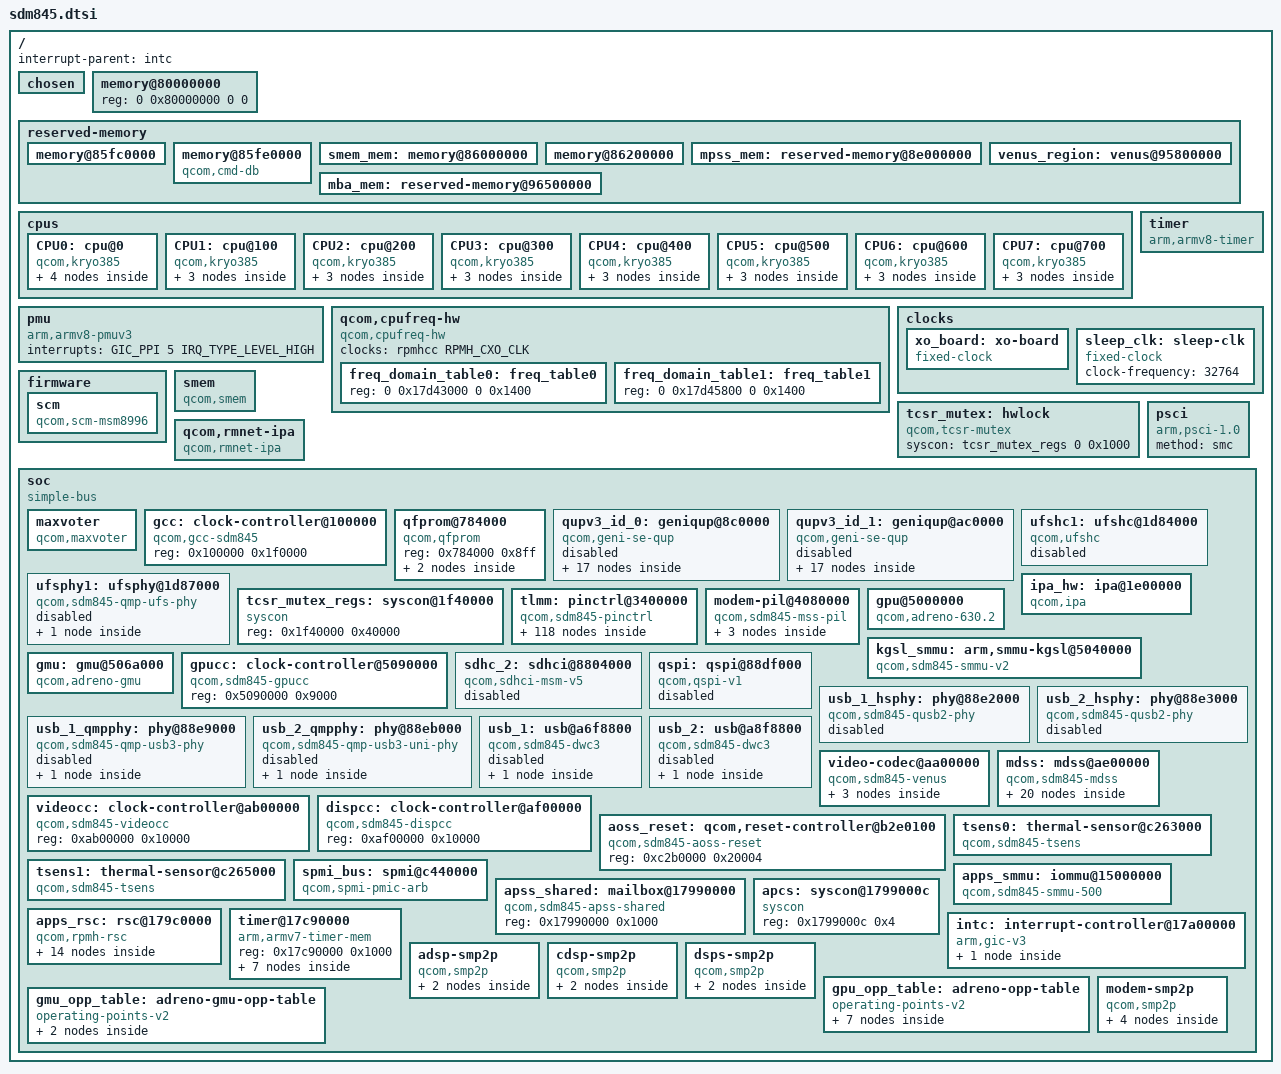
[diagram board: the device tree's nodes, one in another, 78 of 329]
// SPDX-License-Identifier: GPL-2.0
/*
 * SDM845 SoC device tree source
 *
 * Copyright (c) 2018, The Linux Foundation. All rights reserved.
 */

#include <dt-bindings/clock/qcom,dispcc-sdm845.h>
#include <dt-bindings/clock/qcom,gcc-sdm845.h>
#include <dt-bindings/clock/qcom,gpucc-sdm845.h>
#include <dt-bindings/clock/qcom,rpmh.h>
#include <dt-bindings/clock/qcom,videocc-sdm845.h>
#include <dt-bindings/gpio/gpio.h>
#include <dt-bindings/interrupt-controller/arm-gic.h>
#include <dt-bindings/phy/phy-qcom-qusb2.h>
#include <dt-bindings/power/qcom-rpmpd.h>
#include <dt-bindings/reset/qcom,sdm845-aoss.h>
#include <dt-bindings/soc/qcom,rpmh-rsc.h>
#include <dt-bindings/soc/qcom,ipa.h>

/ {
	interrupt-parent = <&intc>;

	#address-cells = <2>;
	#size-cells = <2>;

	chosen { };

	memory@80000000 {
		device_type = "memory";
		/* We expect the bootloader to fill in the size */
		reg = <0 0x80000000 0 0>;
	};

	reserved-memory {
		#address-cells = <2>;
		#size-cells = <2>;
		ranges;

		memory@85fc0000 {
			reg = <0 0x85fc0000 0 0x20000>;
			no-map;
		};

		memory@85fe0000 {
			compatible = "qcom,cmd-db";
			reg = <0x0 0x85fe0000 0x0 0x20000>;
			no-map;
		};

		smem_mem: memory@86000000 {
			reg = <0x0 0x86000000 0x0 0x200000>;
			no-map;
		};

		memory@86200000 {
			reg = <0 0x86200000 0 0x2d00000>;
			no-map;
		};

		mpss_mem: reserved-memory@8e000000 {
			no-map;
			reg = <0 0x8e000000 0 0x7800000>;
		};

		venus_region: venus@95800000 {
			reg = <0x0 0x95800000 0x0 0x500000>;
			no-map;
		};

		mba_mem: reserved-memory@96500000 {
			no-map;
			reg = <0 0x96500000 0 0x200000>;
		};
	};

	cpus {
		#address-cells = <2>;
		#size-cells = <0>;

		CPU0: cpu@0 {
			device_type = "cpu";
			compatible = "qcom,kryo385";
			reg = <0x0 0x0>;
			enable-method = "psci";
			efficiency = <1024>;
			next-level-cache = <&L2_0>;
			qcom,freq-domain = <&freq_domain_table0>;

			L2_0: l2-cache {
				compatible = "cache";
				next-level-cache = <&L3_0>;

				L3_0: l3-cache {
				      compatible = "cache";
				};
			};

			L1_I_0: l1-icache {
				compatible = "cache";
				qcom,dump-size = <0x9000>;
			};

			L1_D_0: l1-dcache {
				compatible = "cache";
				qcom,dump-size = <0x9000>;
			};
		};

		CPU1: cpu@100 {
			device_type = "cpu";
			compatible = "qcom,kryo385";
			reg = <0x0 0x100>;
			enable-method = "psci";
			efficiency = <1024>;
			next-level-cache = <&L2_100>;
			qcom,freq-domain = <&freq_domain_table0>;

			L2_100: l2-cache {
				compatible = "cache";
				next-level-cache = <&L3_0>;
			};

			L1_I_100: l1-icache {
				compatible = "cache";
				qcom,dump-size = <0x9000>;
			};

			L1_D_100: l1-dcache {
				compatible = "cache";
				qcom,dump-size = <0x9000>;
			};
		};

		CPU2: cpu@200 {
			device_type = "cpu";
			compatible = "qcom,kryo385";
			reg = <0x0 0x200>;
			enable-method = "psci";
			efficiency = <1024>;
			next-level-cache = <&L2_200>;
			qcom,freq-domain = <&freq_domain_table0>;

			L2_200: l2-cache {
				compatible = "cache";
				next-level-cache = <&L3_0>;
			};

			L1_I_200: l1-icache {
				compatible = "cache";
				qcom,dump-size = <0x9000>;
			};

			L1_D_200: l1-dcache {
				compatible = "cache";
				qcom,dump-size = <0x9000>;
			};
		};

		CPU3: cpu@300 {
			device_type = "cpu";
			compatible = "qcom,kryo385";
			reg = <0x0 0x300>;
			enable-method = "psci";
			efficiency = <1024>;
			next-level-cache = <&L2_300>;
			qcom,freq-domain = <&freq_domain_table0>;

			L2_300: l2-cache {
				compatible = "cache";
				next-level-cache = <&L3_0>;
			};

			L1_I_300: l1-icache {
				compatible = "cache";
				qcom,dump-size = <0x9000>;
			};
			L1_D_300: l1-dcache {
				compatible = "cache";
				qcom,dump-size = <0x9000>;
			};
		};

		CPU4: cpu@400 {
			device_type = "cpu";
			compatible = "qcom,kryo385";
			reg = <0x0 0x400>;
			enable-method = "psci";
			efficiency = <1740>;
			next-level-cache = <&L2_400>;
			qcom,freq-domain = <&freq_domain_table1>;

			L2_400: l2-cache {
				compatible = "cache";
				next-level-cache = <&L3_0>;
			};

			L1_I_400: l1-icache {
				compatible = "cache";
				qcom,dump-size = <0x12000>;
			};

			L1_D_400: l1-dcache {
				compatible = "cache";
				qcom,dump-size = <0x12000>;
			};
		};

		CPU5: cpu@500 {
			device_type = "cpu";
			compatible = "qcom,kryo385";
			reg = <0x0 0x500>;
			enable-method = "psci";
			efficiency = <1740>;
			next-level-cache = <&L2_500>;
			qcom,freq-domain = <&freq_domain_table1>;

			L2_500: l2-cache {
				compatible = "cache";
				next-level-cache = <&L3_0>;
			};

			L1_I_500: l1-icache {
				compatible = "cache";
				qcom,dump-size = <0x12000>;
			};

			L1_D_500: l1-dcache {
				compatible = "cache";
				qcom,dump-size = <0x12000>;
			};
		};

		CPU6: cpu@600 {
			device_type = "cpu";
			compatible = "qcom,kryo385";
			reg = <0x0 0x600>;
			enable-method = "psci";
			efficiency = <1740>;
			next-level-cache = <&L2_600>;
			qcom,freq-domain = <&freq_domain_table1>;

			L2_600: l2-cache {
				compatible = "cache";
				next-level-cache = <&L3_0>;
			};

			L1_I_600: l1-icache {
				compatible = "cache";
				qcom,dump-size = <0x12000>;
			};

			L1_D_600: l1-dcache {
				compatible = "cache";
				qcom,dump-size = <0x12000>;
			};
		};

		CPU7: cpu@700 {
			device_type = "cpu";
			compatible = "qcom,kryo385";
			reg = <0x0 0x700>;
			enable-method = "psci";
			efficiency = <1740>;
			next-level-cache = <&L2_700>;
			qcom,freq-domain = <&freq_domain_table1>;

			L2_700: l2-cache {
				compatible = "cache";
				next-level-cache = <&L3_0>;
			};

			L1_I_700: l1-icache {
				compatible = "cache";
				qcom,dump-size = <0x12000>;
			};

			L1_D_700: l1-dcache {
				compatible = "cache";
				qcom,dump-size = <0x12000>;
			};
		};
	};

	pmu {
		compatible = "arm,armv8-pmuv3";
		interrupts = <GIC_PPI 5 IRQ_TYPE_LEVEL_HIGH>;
	};

	qcom,cpufreq-hw {
		compatible = "qcom,cpufreq-hw";

		clocks = <&rpmhcc RPMH_CXO_CLK>;
		clock-names = "xo";

		#address-cells = <2>;
		#size-cells = <2>;
		ranges;
		freq_domain_table0: freq_table0 {
			reg = <0 0x17d43000 0 0x1400>;
		};

		freq_domain_table1: freq_table1 {
			reg = <0 0x17d45800 0 0x1400>;
		};
	};

	timer {
		compatible = "arm,armv8-timer";
		interrupts = <GIC_PPI 1 IRQ_TYPE_LEVEL_LOW>,
			     <GIC_PPI 2 IRQ_TYPE_LEVEL_LOW>,
			     <GIC_PPI 3 IRQ_TYPE_LEVEL_LOW>,
			     <GIC_PPI 0 IRQ_TYPE_LEVEL_LOW>;
	};

	clocks {
		xo_board: xo-board {
			compatible = "fixed-clock";
			#clock-cells = <0>;
			clock-frequency = <38400000>;
			clock-output-names = "xo_board";
		};

		sleep_clk: sleep-clk {
			compatible = "fixed-clock";
			#clock-cells = <0>;
			clock-frequency = <32764>;
		};
	};

	firmware {
		/* TODO: does this really belong in SoC dtsi file? */
		scm {
			compatible = "qcom,scm-msm8996";
		};
	};

	tcsr_mutex: hwlock {
		compatible = "qcom,tcsr-mutex";
		syscon = <&tcsr_mutex_regs 0 0x1000>;
		#hwlock-cells = <1>;
	};

	smem {
		compatible = "qcom,smem";
		memory-region = <&smem_mem>;
		hwlocks = <&tcsr_mutex 3>;
	};

	psci {
		compatible = "arm,psci-1.0";
		method = "smc";
	};

	qcom,rmnet-ipa {
		compatible = "qcom,rmnet-ipa";
	};

	soc: soc {
		#address-cells = <1>;
		#size-cells = <1>;
		ranges = <0 0 0 0xffffffff>;
		compatible = "simple-bus";

		maxvoter {
			compatible = "qcom,maxvoter";
			power-domains = <&rpmhpd SDM845_MX>,
					<&rpmhpd SDM845_CX>;
			power-domain-names = "mx", "cx";
		};

		gcc: clock-controller@100000 {
			compatible = "qcom,gcc-sdm845";
			reg = <0x100000 0x1f0000>;
			#clock-cells = <1>;
			#reset-cells = <1>;
			#power-domain-cells = <1>;
		};

		qfprom@784000 {
			compatible = "qcom,qfprom";
			reg = <0x784000 0x8ff>;
			#address-cells = <1>;
			#size-cells = <1>;

			qusb2p_hstx_trim: hstx-trim-primary@1eb {
				reg = <0x1eb 0x1>;
				bits = <1 4>;
			};

			qusb2s_hstx_trim: hstx-trim-secondary@1eb {
				reg = <0x1eb 0x2>;
				bits = <6 4>;
			};
		};

		qupv3_id_0: geniqup@8c0000 {
			compatible = "qcom,geni-se-qup";
			reg = <0x8c0000 0x6000>;
			clock-names = "m-ahb", "s-ahb";
			clocks = <&gcc GCC_QUPV3_WRAP_0_M_AHB_CLK>,
				 <&gcc GCC_QUPV3_WRAP_0_S_AHB_CLK>;
			#address-cells = <1>;
			#size-cells = <1>;
			ranges;
			status = "disabled";

			i2c0: i2c@880000 {
				compatible = "qcom,geni-i2c";
				reg = <0x880000 0x4000>;
				clock-names = "se";
				clocks = <&gcc GCC_QUPV3_WRAP0_S0_CLK>;
				pinctrl-names = "default";
				pinctrl-0 = <&qup_i2c0_default>;
				interrupts = <GIC_SPI 601 IRQ_TYPE_LEVEL_HIGH>;
				#address-cells = <1>;
				#size-cells = <0>;
				status = "disabled";
			};

			spi0: spi@880000 {
				compatible = "qcom,geni-spi";
				reg = <0x880000 0x4000>;
				clock-names = "se";
				clocks = <&gcc GCC_QUPV3_WRAP0_S0_CLK>;
				cs-gpios = <&tlmm 3 GPIO_ACTIVE_HIGH>;
				pinctrl-names = "default";
				pinctrl-0 = <&qup_spi0_default>;
				interrupts = <GIC_SPI 601 IRQ_TYPE_LEVEL_HIGH>;
				#address-cells = <1>;
				#size-cells = <0>;
				status = "disabled";
			};

			i2c1: i2c@884000 {
				compatible = "qcom,geni-i2c";
				reg = <0x884000 0x4000>;
				clock-names = "se";
				clocks = <&gcc GCC_QUPV3_WRAP0_S1_CLK>;
				pinctrl-names = "default";
				pinctrl-0 = <&qup_i2c1_default>;
				interrupts = <GIC_SPI 602 IRQ_TYPE_LEVEL_HIGH>;
				#address-cells = <1>;
				#size-cells = <0>;
				status = "disabled";
			};

			spi1: spi@884000 {
				compatible = "qcom,geni-spi";
				reg = <0x884000 0x4000>;
				clock-names = "se";
				clocks = <&gcc GCC_QUPV3_WRAP0_S1_CLK>;
				cs-gpios = <&tlmm 20 GPIO_ACTIVE_HIGH>;
				pinctrl-names = "default";
				pinctrl-0 = <&qup_spi1_default>;
				interrupts = <GIC_SPI 602 IRQ_TYPE_LEVEL_HIGH>;
				#address-cells = <1>;
				#size-cells = <0>;
				status = "disabled";
			};

			i2c2: i2c@888000 {
				compatible = "qcom,geni-i2c";
				reg = <0x888000 0x4000>;
				clock-names = "se";
				clocks = <&gcc GCC_QUPV3_WRAP0_S2_CLK>;
				pinctrl-names = "default";
				pinctrl-0 = <&qup_i2c2_default>;
				interrupts = <GIC_SPI 603 IRQ_TYPE_LEVEL_HIGH>;
				#address-cells = <1>;
				#size-cells = <0>;
				status = "disabled";
			};

			spi2: spi@888000 {
				compatible = "qcom,geni-spi";
				reg = <0x888000 0x4000>;
				clock-names = "se";
				clocks = <&gcc GCC_QUPV3_WRAP0_S2_CLK>;
				cs-gpios = <&tlmm 30 GPIO_ACTIVE_HIGH>;
				pinctrl-names = "default";
				pinctrl-0 = <&qup_spi2_default>;
				interrupts = <GIC_SPI 603 IRQ_TYPE_LEVEL_HIGH>;
				#address-cells = <1>;
				#size-cells = <0>;
				status = "disabled";
			};

			i2c3: i2c@88c000 {
				compatible = "qcom,geni-i2c";
				reg = <0x88c000 0x4000>;
				clock-names = "se";
				clocks = <&gcc GCC_QUPV3_WRAP0_S3_CLK>;
				pinctrl-names = "default";
				pinctrl-0 = <&qup_i2c3_default>;
				interrupts = <GIC_SPI 604 IRQ_TYPE_LEVEL_HIGH>;
				#address-cells = <1>;
				#size-cells = <0>;
				status = "disabled";
			};

			spi3: spi@88c000 {
				compatible = "qcom,geni-spi";
				reg = <0x88c000 0x4000>;
				clock-names = "se";
				clocks = <&gcc GCC_QUPV3_WRAP0_S3_CLK>;
				cs-gpios = <&tlmm 44 GPIO_ACTIVE_HIGH>;
				pinctrl-names = "default";
				pinctrl-0 = <&qup_spi3_default>;
				interrupts = <GIC_SPI 604 IRQ_TYPE_LEVEL_HIGH>;
				#address-cells = <1>;
				#size-cells = <0>;
				status = "disabled";
			};

			i2c4: i2c@890000 {
				compatible = "qcom,geni-i2c";
				reg = <0x890000 0x4000>;
				clock-names = "se";
				clocks = <&gcc GCC_QUPV3_WRAP0_S4_CLK>;
				pinctrl-names = "default";
				pinctrl-0 = <&qup_i2c4_default>;
				interrupts = <GIC_SPI 605 IRQ_TYPE_LEVEL_HIGH>;
				#address-cells = <1>;
				#size-cells = <0>;
				status = "disabled";
			};

			spi4: spi@890000 {
				compatible = "qcom,geni-spi";
				reg = <0x890000 0x4000>;
				clock-names = "se";
				clocks = <&gcc GCC_QUPV3_WRAP0_S4_CLK>;
				cs-gpios = <&tlmm 92 GPIO_ACTIVE_HIGH>;
				pinctrl-names = "default";
				pinctrl-0 = <&qup_spi4_default>;
				interrupts = <GIC_SPI 605 IRQ_TYPE_LEVEL_HIGH>;
				#address-cells = <1>;
				#size-cells = <0>;
				status = "disabled";
			};

			i2c5: i2c@894000 {
				compatible = "qcom,geni-i2c";
				reg = <0x894000 0x4000>;
				clock-names = "se";
				clocks = <&gcc GCC_QUPV3_WRAP0_S5_CLK>;
				pinctrl-names = "default";
				pinctrl-0 = <&qup_i2c5_default>;
				interrupts = <GIC_SPI 606 IRQ_TYPE_LEVEL_HIGH>;
				#address-cells = <1>;
				#size-cells = <0>;
				status = "disabled";
			};

			spi5: spi@894000 {
				compatible = "qcom,geni-spi";
				reg = <0x894000 0x4000>;
				clock-names = "se";
				clocks = <&gcc GCC_QUPV3_WRAP0_S5_CLK>;
				cs-gpios = <&tlmm 88 GPIO_ACTIVE_HIGH>;
				pinctrl-names = "default";
				pinctrl-0 = <&qup_spi5_default>;
				interrupts = <GIC_SPI 606 IRQ_TYPE_LEVEL_HIGH>;
				#address-cells = <1>;
				#size-cells = <0>;
				status = "disabled";
			};

			i2c6: i2c@898000 {
				compatible = "qcom,geni-i2c";
				reg = <0x898000 0x4000>;
				clock-names = "se";
				clocks = <&gcc GCC_QUPV3_WRAP0_S6_CLK>;
				pinctrl-names = "default";
				pinctrl-0 = <&qup_i2c6_default>;
				interrupts = <GIC_SPI 607 IRQ_TYPE_LEVEL_HIGH>;
				#address-cells = <1>;
				#size-cells = <0>;
				status = "disabled";
			};

			spi6: spi@898000 {
				compatible = "qcom,geni-spi";
				reg = <0x898000 0x4000>;
				clock-names = "se";
				clocks = <&gcc GCC_QUPV3_WRAP0_S6_CLK>;
				cs-gpios = <&tlmm 48 GPIO_ACTIVE_HIGH>;
				pinctrl-names = "default";
				pinctrl-0 = <&qup_spi6_default>;
				interrupts = <GIC_SPI 607 IRQ_TYPE_LEVEL_HIGH>;
				#address-cells = <1>;
				#size-cells = <0>;
				status = "disabled";
			};

			uart6: serial@898000 {
				compatible = "qcom,geni-uart";
				reg = <0x898000 0x4000>;
				clock-names = "se";
				clocks = <&gcc GCC_QUPV3_WRAP0_S6_CLK>;
				pinctrl-names = "default";
				pinctrl-0 = <&qup_uart9_default>;
				interrupts = <GIC_SPI 607 IRQ_TYPE_LEVEL_HIGH>;
				status = "disabled";
			};

			i2c7: i2c@89c000 {
				compatible = "qcom,geni-i2c";
				reg = <0x89c000 0x4000>;
				clock-names = "se";
				clocks = <&gcc GCC_QUPV3_WRAP0_S7_CLK>;
				pinctrl-names = "default";
				pinctrl-0 = <&qup_i2c7_default>;
				interrupts = <GIC_SPI 608 IRQ_TYPE_LEVEL_HIGH>;
				#address-cells = <1>;
				#size-cells = <0>;
				status = "disabled";
			};

			spi7: spi@89c000 {
				compatible = "qcom,geni-spi";
				reg = <0x89c000 0x4000>;
				clock-names = "se";
				clocks = <&gcc GCC_QUPV3_WRAP0_S7_CLK>;
				cs-gpios = <&tlmm 96 GPIO_ACTIVE_HIGH>;
				pinctrl-names = "default";
				pinctrl-0 = <&qup_spi7_default>;
				interrupts = <GIC_SPI 608 IRQ_TYPE_LEVEL_HIGH>;
				#address-cells = <1>;
				#size-cells = <0>;
				status = "disabled";
			};
		};

		qupv3_id_1: geniqup@ac0000 {
			compatible = "qcom,geni-se-qup";
			reg = <0xac0000 0x6000>;
			clock-names = "m-ahb", "s-ahb";
			clocks = <&gcc GCC_QUPV3_WRAP_1_M_AHB_CLK>,
				 <&gcc GCC_QUPV3_WRAP_1_S_AHB_CLK>;
			#address-cells = <1>;
			#size-cells = <1>;
			ranges;
			status = "disabled";

			i2c8: i2c@a80000 {
				compatible = "qcom,geni-i2c";
				reg = <0xa80000 0x4000>;
				clock-names = "se";
				clocks = <&gcc GCC_QUPV3_WRAP1_S0_CLK>;
				pinctrl-names = "default";
				pinctrl-0 = <&qup_i2c8_default>;
				interrupts = <GIC_SPI 353 IRQ_TYPE_LEVEL_HIGH>;
				#address-cells = <1>;
				#size-cells = <0>;
				status = "disabled";
			};

			spi8: spi@a80000 {
				compatible = "qcom,geni-spi";
				reg = <0xa80000 0x4000>;
				clock-names = "se";
				clocks = <&gcc GCC_QUPV3_WRAP1_S0_CLK>;
				cs-gpios = <&tlmm 68 GPIO_ACTIVE_HIGH>;
				pinctrl-names = "default";
				pinctrl-0 = <&qup_spi8_default>;
				interrupts = <GIC_SPI 353 IRQ_TYPE_LEVEL_HIGH>;
				#address-cells = <1>;
				#size-cells = <0>;
				status = "disabled";
			};

			i2c9: i2c@a84000 {
				compatible = "qcom,geni-i2c";
				reg = <0xa84000 0x4000>;
				clock-names = "se";
				clocks = <&gcc GCC_QUPV3_WRAP1_S1_CLK>;
				pinctrl-names = "default";
				pinctrl-0 = <&qup_i2c9_default>;
				interrupts = <GIC_SPI 354 IRQ_TYPE_LEVEL_HIGH>;
				#address-cells = <1>;
				#size-cells = <0>;
				status = "disabled";
			};

			spi9: spi@a84000 {
				compatible = "qcom,geni-spi";
				reg = <0xa84000 0x4000>;
				clock-names = "se";
				clocks = <&gcc GCC_QUPV3_WRAP1_S1_CLK>;
				cs-gpios = <&tlmm 5 GPIO_ACTIVE_HIGH>;
				pinctrl-names = "default";
				pinctrl-0 = <&qup_spi9_default>;
				interrupts = <GIC_SPI 354 IRQ_TYPE_LEVEL_HIGH>;
				#address-cells = <1>;
				#size-cells = <0>;
				status = "disabled";
			};

			uart9: serial@a84000 {
				compatible = "qcom,geni-debug-uart";
				reg = <0xa84000 0x4000>;
				clock-names = "se";
				clocks = <&gcc GCC_QUPV3_WRAP1_S1_CLK>;
				pinctrl-names = "default";
				pinctrl-0 = <&qup_uart9_default>;
				interrupts = <GIC_SPI 354 IRQ_TYPE_LEVEL_HIGH>;
				status = "disabled";
			};

			i2c10: i2c@a88000 {
				compatible = "qcom,geni-i2c";
				reg = <0xa88000 0x4000>;
				clock-names = "se";
				clocks = <&gcc GCC_QUPV3_WRAP1_S2_CLK>;
				pinctrl-names = "default";
				pinctrl-0 = <&qup_i2c10_default>;
				interrupts = <GIC_SPI 355 IRQ_TYPE_LEVEL_HIGH>;
				#address-cells = <1>;
				#size-cells = <0>;
				status = "disabled";
			};

			spi10: spi@a88000 {
				compatible = "qcom,geni-spi";
				reg = <0xa88000 0x4000>;
				clock-names = "se";
				clocks = <&gcc GCC_QUPV3_WRAP1_S2_CLK>;
				cs-gpios = <&tlmm 54 GPIO_ACTIVE_HIGH>;
				pinctrl-names = "default";
				pinctrl-0 = <&qup_spi10_default>;
				interrupts = <GIC_SPI 355 IRQ_TYPE_LEVEL_HIGH>;
				#address-cells = <1>;
				#size-cells = <0>;
				status = "disabled";
			};

			i2c11: i2c@a8c000 {
				compatible = "qcom,geni-i2c";
				reg = <0xa8c000 0x4000>;
				clock-names = "se";
				clocks = <&gcc GCC_QUPV3_WRAP1_S3_CLK>;
				pinctrl-names = "default";
				pinctrl-0 = <&qup_i2c11_default>;
				interrupts = <GIC_SPI 356 IRQ_TYPE_LEVEL_HIGH>;
				#address-cells = <1>;
				#size-cells = <0>;
				status = "disabled";
			};

			spi11: spi@a8c000 {
				compatible = "qcom,geni-spi";
				reg = <0xa8c000 0x4000>;
				clock-names = "se";
				clocks = <&gcc GCC_QUPV3_WRAP1_S3_CLK>;
				cs-gpios = <&tlmm 34 GPIO_ACTIVE_HIGH>;
				pinctrl-names = "default";
				pinctrl-0 = <&qup_spi11_default>;
				interrupts = <GIC_SPI 356 IRQ_TYPE_LEVEL_HIGH>;
				#address-cells = <1>;
				#size-cells = <0>;
				status = "disabled";
			};

			i2c12: i2c@a90000 {
				compatible = "qcom,geni-i2c";
				reg = <0xa90000 0x4000>;
				clock-names = "se";
				clocks = <&gcc GCC_QUPV3_WRAP1_S4_CLK>;
				pinctrl-names = "default";
				pinctrl-0 = <&qup_i2c12_default>;
				interrupts = <GIC_SPI 357 IRQ_TYPE_LEVEL_HIGH>;
				#address-cells = <1>;
				#size-cells = <0>;
				status = "disabled";
			};

			spi12: spi@a90000 {
				compatible = "qcom,geni-spi";
				reg = <0xa90000 0x4000>;
				clock-names = "se";
				clocks = <&gcc GCC_QUPV3_WRAP1_S4_CLK>;
				cs-gpios = <&tlmm 52 GPIO_ACTIVE_HIGH>;
				pinctrl-names = "default";
				pinctrl-0 = <&qup_spi12_default>;
				interrupts = <GIC_SPI 357 IRQ_TYPE_LEVEL_HIGH>;
				#address-cells = <1>;
				#size-cells = <0>;
				status = "disabled";
			};

			i2c13: i2c@a94000 {
				compatible = "qcom,geni-i2c";
				reg = <0xa94000 0x4000>;
				clock-names = "se";
				clocks = <&gcc GCC_QUPV3_WRAP1_S5_CLK>;
				pinctrl-names = "default";
				pinctrl-0 = <&qup_i2c13_default>;
				interrupts = <GIC_SPI 358 IRQ_TYPE_LEVEL_HIGH>;
				#address-cells = <1>;
				#size-cells = <0>;
				status = "disabled";
			};

			spi13: spi@a94000 {
				compatible = "qcom,geni-spi";
				reg = <0xa94000 0x4000>;
				clock-names = "se";
				clocks = <&gcc GCC_QUPV3_WRAP1_S5_CLK>;
				cs-gpios = <&tlmm 108 GPIO_ACTIVE_HIGH>;
				pinctrl-names = "default";
				pinctrl-0 = <&qup_spi13_default>;
				interrupts = <GIC_SPI 358 IRQ_TYPE_LEVEL_HIGH>;
				#address-cells = <1>;
				#size-cells = <0>;
				status = "disabled";
			};

			i2c14: i2c@a98000 {
				compatible = "qcom,geni-i2c";
				reg = <0xa98000 0x4000>;
				clock-names = "se";
				clocks = <&gcc GCC_QUPV3_WRAP1_S6_CLK>;
				pinctrl-names = "default";
				pinctrl-0 = <&qup_i2c14_default>;
				interrupts = <GIC_SPI 359 IRQ_TYPE_LEVEL_HIGH>;
				#address-cells = <1>;
				#size-cells = <0>;
				status = "disabled";
			};

			spi14: spi@a98000 {
				compatible = "qcom,geni-spi";
				reg = <0xa98000 0x4000>;
				clock-names = "se";
				clocks = <&gcc GCC_QUPV3_WRAP1_S6_CLK>;
				cs-gpios = <&tlmm 32 GPIO_ACTIVE_HIGH>;
				pinctrl-names = "default";
				pinctrl-0 = <&qup_spi14_default>;
				interrupts = <GIC_SPI 359 IRQ_TYPE_LEVEL_HIGH>;
				#address-cells = <1>;
				#size-cells = <0>;
				status = "disabled";
			};

			i2c15: i2c@a9c000 {
				compatible = "qcom,geni-i2c";
				reg = <0xa9c000 0x4000>;
				clock-names = "se";
				clocks = <&gcc GCC_QUPV3_WRAP1_S7_CLK>;
				pinctrl-names = "default";
				pinctrl-0 = <&qup_i2c15_default>;
				interrupts = <GIC_SPI 360 IRQ_TYPE_LEVEL_HIGH>;
				#address-cells = <1>;
				#size-cells = <0>;
				status = "disabled";
			};

			spi15: spi@a9c000 {
				compatible = "qcom,geni-spi";
				reg = <0xa9c000 0x4000>;
				clock-names = "se";
				clocks = <&gcc GCC_QUPV3_WRAP1_S7_CLK>;
				cs-gpios = <&tlmm 84 GPIO_ACTIVE_HIGH>;
				pinctrl-names = "default";
				pinctrl-0 = <&qup_spi15_default>;
				interrupts = <GIC_SPI 360 IRQ_TYPE_LEVEL_HIGH>;
				#address-cells = <1>;
				#size-cells = <0>;
				status = "disabled";
			};
		};

		ufshc1: ufshc@1d84000 {
			compatible = "qcom,ufshc";
			reg = <0x1d84000 0x2500>;
			interrupts = <0 265 IRQ_TYPE_LEVEL_HIGH>;
			phys = <&ufsphy1_l0>;
			phy-names = "ufsphy";

			lanes-per-direction = <2>;
			dev-ref-clk-freq = <0>; /* 19.2 MHz */

			power-domains = <&gcc UFS_PHY_GDSC>;

			clock-names =
				"core_clk",
				"bus_aggr_clk",
				"iface_clk",
				"core_clk_unipro",
				"ref_clk",
				"tx_lane0_sync_clk",
				"rx_lane0_sync_clk",
				"rx_lane1_sync_clk";
			clocks =
				<&gcc GCC_UFS_PHY_AXI_CLK>,
				<&gcc GCC_AGGRE_UFS_PHY_AXI_CLK>,
				<&gcc GCC_UFS_PHY_AHB_CLK>,
				<&gcc GCC_UFS_PHY_UNIPRO_CORE_CLK>,
				<&rpmhcc RPMH_CXO_CLK>,
				<&gcc GCC_UFS_PHY_TX_SYMBOL_0_CLK>,
				<&gcc GCC_UFS_PHY_RX_SYMBOL_0_CLK>,
				<&gcc GCC_UFS_PHY_RX_SYMBOL_1_CLK>;
			freq-table-hz =
				<50000000 200000000>,
				<0 0>,
				<0 0>,
				<37500000 150000000>,
				<0 0>,
				<0 0>,
				<0 0>,
				<0 0>;

			non-removable;

			resets = <&gcc GCC_UFS_PHY_BCR>;
			reset-names = "core_reset";

			status = "disabled";
		};

		ufsphy1: ufsphy@1d87000 {
			compatible = "qcom,sdm845-qmp-ufs-phy";
			reg = <0x1d87000 0x18c>;
			#clock-cells = <1>;
			#address-cells = <1>;
			#size-cells = <1>;
			ranges;
			clock-names = "ref_clk_src",
				      "ref",
				      "ref_aux";
			clocks = <&rpmhcc RPMH_CXO_CLK>,
				 <&gcc GCC_UFS_MEM_CLKREF_CLK>,
				 <&gcc GCC_UFS_PHY_PHY_AUX_CLK>;

			status = "disabled";

			ufsphy1_l0: lane@0x1d87400 {
				reg = <0x1d87400 0x108>,
				      <0x1d87600 0x1e0>,
				      <0x1d87c00 0x1dc>;
				#phy-cells = <0>;
			};
		};

		ipa_hw: ipa@1e00000 {
			compatible = "qcom,ipa";

			qcom,ipa-hw-ver = <QCOM_IPA_HW_VER_v3_5_1>;
			qcom,ee = <0>;

			reg = <0x1e00000 0x34000>,
			      <0x1e04000 0x2c000>;
			reg-names = "ipa-base",
				    "gsi-base";

			interrupts-extended = <&intc 0 311 IRQ_TYPE_LEVEL_HIGH>,
					      <&intc 0 432 IRQ_TYPE_LEVEL_HIGH>,
					      <&ipa_smp2p_in 0 IRQ_TYPE_LEVEL_HIGH>;
			interrupt-names = "ipa-irq",
					  "gsi-irq",
					  "ipa-clock-query";

			qcom,smem-states = <&ipa_smp2p_out 0>,
					   <&ipa_smp2p_out 1>;
			qcom,smem-state-names = "ipa-clock-enabled-valid",
						"ipa-clock-enabled";
		};

		tcsr_mutex_regs: syscon@1f40000 {
			compatible = "syscon";
			reg = <0x1f40000 0x40000>;
		};

		tlmm: pinctrl@3400000 {
			compatible = "qcom,sdm845-pinctrl";
			reg = <0x03400000 0xc00000>;
			interrupts = <GIC_SPI 208 IRQ_TYPE_LEVEL_HIGH>;
			gpio-controller;
			#gpio-cells = <2>;
			interrupt-controller;
			#interrupt-cells = <2>;

			dpu_dp_aux_active: dpu-dp-aux_active {
				pinmux {
					pins = "gpio43", "gpio51";
					function = "gpio";
				};

				/* TODO: move pinconf to board file */
				pinconf {
					pins = "gpio43", "gpio51";
					bias-disable;
					drive-strength = <8>;
				};
			};

			dpu_dp_aux_suspend: dpu-dp-aux-suspend {
				pinmux {
					pins = "gpio43", "gpio51";
					function = "gpio";
				};

				/* TODO: move pinconf to board file */
				pinconf {
					pins = "gpio43", "gpio51";
					bias-pull-down;
					drive-strength = <2>;
				};
			};

			dpu_dp_usbplug_cc_active: dpu-dp-usbplug-cc-active {
				pinmux {
					pins = "gpio38";
					function = "gpio";
				};

				/* TODO: move pinconf to board file */
				pinconf {
					pins = "gpio38";
					bias-disable;
					drive-strength = <16>;
				};
			};

			dpu_dp_usbplug_cc_suspend: dpu-dp-usbplug-cc-suspend {
				pinmux {
					pins = "gpio38";
					function = "gpio";
				};

				/* TODO: move pinconf to board file */
				pinconf {
					pins = "gpio38";
					bias-pull-down;
					drive-strength = <2>;
				};
			};

			dpu_dsi_active: dpu-dsi-active {
				pinmux {
					pins = "gpio6", "gpio52";
					function = "gpio";
				};

				/* TODO: move pinconf to board file */
				pinconf {
					pins = "gpio6", "gpio52";
					drive-strength = <8>;
					/*bias-pull-up; */
					bias-disable;
				};
			};
			dpu_dsi_suspend: dpu-dsi-suspend {
				pinmux {
					pins = "gpio6", "gpio52";
					function = "gpio";
				};

				/* TODO: move pinconf to board file */
				pinconf {
					pins = "gpio6", "gpio52";
					drive-strength = <2>;
					bias-pull-down;
				};
			};

			dpu_te_active: dpu-te-active {
				pinmux {
					pins = "gpio10";
					function = "mdp_vsync";
				};

				/* TODO: move pinconf to board file */
				pinconf {
					pins = "gpio10";
					drive-strength = <2>;
					bias-pull-down;
				};
			};

			dpu_te_suspend: dpu-te-suspend {
				pinmux {
					pins = "gpio10";
					function = "mdp_vsync";
				};

				/* TODO: move pinconf to board file */
				pinconf {
					pins = "gpio10";
					drive-strength = <2>;
					bias-pull-down;
				};
			};

			qspi_clk: qspi-clk {
				pinmux {
					pins = "gpio95";
					function = "qspi_clk";
				};
			};

			qspi_cs0: qspi-cs0 {
				pinmux {
					pins = "gpio90";
					function = "qspi_cs";
				};
			};

			qspi_cs1: qspi-cs1 {
				pinmux {
					pins = "gpio89";
					function = "qspi_cs";
				};
			};

			qspi_data01: qspi-data01 {
				pinmux-data {
					pins = "gpio91", "gpio92";
					function = "qspi_data";
				};
			};

			qspi_data12: qspi-data12 {
				pinmux-data {
					pins = "gpio93", "gpio94";
					function = "qspi_data";
				};
			};

			qup_i2c0_default: qup-i2c0-default {
				pinmux {
					pins = "gpio0", "gpio1";
					function = "qup0";
				};
			};

			qup_i2c1_default: qup-i2c1-default {
				pinmux {
					pins = "gpio17", "gpio18";
					function = "qup1";
				};
			};

			qup_i2c2_default: qup-i2c2-default {
				pinmux {
					pins = "gpio27", "gpio28";
					function = "qup2";
				};
			};

			qup_i2c3_default: qup-i2c3-default {
				pinmux {
					pins = "gpio41", "gpio42";
					function = "qup3";
				};
			};

			qup_i2c4_default: qup-i2c4-default {
				pinmux {
					pins = "gpio89", "gpio90";
					function = "qup4";
				};
			};

			qup_i2c5_default: qup-i2c5-default {
				pinmux {
					pins = "gpio85", "gpio86";
					function = "qup5";
				};
			};

			qup_i2c6_default: qup-i2c6-default {
				pinmux {
					pins = "gpio45", "gpio46";
					function = "qup6";
				};
			};

			qup_i2c7_default: qup-i2c7-default {
				pinmux {
					pins = "gpio93", "gpio94";
					function = "qup7";
				};
			};

			qup_i2c8_default: qup-i2c8-default {
				pinmux {
					pins = "gpio65", "gpio66";
					function = "qup8";
				};
			};

			qup_i2c9_default: qup-i2c9-default {
				pinmux {
					pins = "gpio6", "gpio7";
					function = "qup9";
				};
			};

			qup_i2c10_default: qup-i2c10-default {
				pinmux {
					pins = "gpio55", "gpio56";
					function = "qup10";
				};
			};

			qup_i2c11_default: qup-i2c11-default {
				pinmux {
					pins = "gpio31", "gpio32";
					function = "qup11";
				};
			};

			qup_i2c12_default: qup-i2c12-default {
				pinmux {
					pins = "gpio49", "gpio50";
					function = "qup12";
				};
			};

			qup_i2c13_default: qup-i2c13-default {
				pinmux {
					pins = "gpio105", "gpio106";
					function = "qup13";
				};
			};

			qup_i2c14_default: qup-i2c14-default {
				pinmux {
					pins = "gpio33", "gpio34";
					function = "qup14";
				};
			};

			qup_i2c15_default: qup-i2c15-default {
				pinmux {
					pins = "gpio81", "gpio82";
					function = "qup15";
				};
			};

			qup_spi0_default: qup-spi0-default {
				pinmux {
					pins = "gpio0", "gpio1",
					       "gpio2";
					function = "qup0";
				};
				pinmux-cs {
					pins = "gpio3";
					function = "gpio";
					output-high;
				};
			};

			qup_spi1_default: qup-spi1-default {
				pinmux {
					pins = "gpio17", "gpio18",
					       "gpio19";
					function = "qup1";
				};
				pinmux-cs {
					pins = "gpio20";
					function = "gpio";
					output-high;
				};
			};

			qup_spi2_default: qup-spi2-default {
				pinmux {
					pins = "gpio27", "gpio28",
					       "gpio29";
					function = "qup2";
				};
				pinmux-cs {
					pins = "gpio30";
					function = "gpio";
					output-high;
				};
			};

			qup_spi3_default: qup-spi3-default {
				pinmux {
					pins = "gpio41", "gpio42",
					       "gpio43";
					function = "qup3";
				};
				pinmux-cs {
					pins = "gpio44";
					function = "gpio";
					output-high;
				};
			};

			qup_spi4_default: qup-spi4-default {
				pinmux {
					pins = "gpio89", "gpio90",
					       "gpio91";
					function = "qup4";
				};
				pinmux-cs {
					pins = "gpio92";
					function = "gpio";
					output-high;
				};
			};

			qup_spi5_default: qup-spi5-default {
				pinmux {
					pins = "gpio85", "gpio86",
					       "gpio87";
					function = "qup5";
				};
				pinmux-cs {
					pins = "gpio88";
					function = "gpio";
					output-high;
				};
			};

			qup_spi6_default: qup-spi6-default {
				pinmux {
					pins = "gpio45", "gpio46",
					       "gpio47";
					function = "qup6";
				};
				pinmux-cs {
					pins = "gpio48";
					function = "gpio";
					output-high;
				};
			};

			qup_spi7_default: qup-spi7-default {
				pinmux {
					pins = "gpio93", "gpio94",
					       "gpio95";
					function = "qup7";
				};
				pinmux-cs {
					pins = "gpio96";
					function = "gpio";
					output-high;
				};
			};

			qup_spi8_default: qup-spi8-default {
				pinmux {
					pins = "gpio65", "gpio66",
					       "gpio67";
					function = "qup8";
				};
				pinmux-cs {
					pins = "gpio68";
					function = "gpio";
					output-high;
				};
			};

			qup_spi9_default: qup-spi9-default {
				pinmux {
					pins = "gpio6", "gpio7",
					       "gpio4";
					function = "qup9";
				};
				pinmux-cs {
					pins = "gpio5";
					function = "gpio";
					output-high;
				};
			};

			qup_spi10_default: qup-spi10-default {
				pinmux {
					pins = "gpio55", "gpio56",
					       "gpio53";
					function = "qup10";
				};
				pinmux-cs {
					pins = "gpio54";
					function = "gpio";
					output-high;
				};
			};

			qup_spi11_default: qup-spi11-default {
				pinmux {
					pins = "gpio31", "gpio32",
					       "gpio33";
					function = "qup11";
				};
				pinmux-cs {
					pins = "gpio34";
					function = "gpio";
					output-high;
				};
			};

			qup_spi12_default: qup-spi12-default {
				pinmux {
					pins = "gpio49", "gpio50",
					       "gpio51";
					function = "qup12";
				};
				pinmux-cs {
					pins = "gpio52";
					function = "gpio";
					output-high;
				};
			};

			qup_spi13_default: qup-spi13-default {
				pinmux {
					pins = "gpio105", "gpio106",
					       "gpio107";
					function = "qup13";
				};
				pinmux-cs {
					pins = "gpio108";
					function = "gpio";
					output-high;
				};
			};

			qup_spi14_default: qup-spi14-default {
				pinmux {
					pins = "gpio33", "gpio34",
					       "gpio31";
					function = "qup14";
				};
				pinmux-cs {
					pins = "gpio32";
					function = "gpio";
					output-high;
				};
			};

			qup_spi15_default: qup-spi15-default {
				pinmux {
					pins = "gpio81", "gpio82",
					       "gpio83";
					function = "qup15";
				};
				pinmux-cs {
					pins = "gpio84";
					function = "gpio";
					output-high;
				};
			};

			qup_uart6_default: qup-uart6-default {
				pinmux {
					function = "qup6";
					pins = "gpio45", "gpio46";
				};
			};

			qup_uart9_default: qup-uart9-default {
				pinmux {
					pins = "gpio4", "gpio5";
					function = "qup9";
				};
			};
		};

		modem-pil@4080000 {
			compatible = "qcom,sdm845-mss-pil";
			reg = <0x04080000 0x408>, <0x04180000 0x48>;

			reg-names = "qdsp6", "rmb";

			interrupts-extended = <&intc 0 266 1>,
					      <&modem_smp2p_in 0 IRQ_TYPE_LEVEL_HIGH>,
					      <&modem_smp2p_in 1 IRQ_TYPE_LEVEL_HIGH>,
					      <&modem_smp2p_in 2 IRQ_TYPE_LEVEL_HIGH>,
					      <&modem_smp2p_in 3 IRQ_TYPE_LEVEL_HIGH>;

			interrupt-names = "wdog", "fatal", "ready",
					  "handover", "stop-ack";

			clocks = <&gcc GCC_MSS_CFG_AHB_CLK>,
				 <&gcc GCC_MSS_Q6_MEMNOC_AXI_CLK>,
				 <&gcc GCC_BOOT_ROM_AHB_CLK>,
				 <&gcc GCC_MSS_GPLL0_DIV_CLK_SRC>,
				 <&gcc GCC_MSS_SNOC_AXI_CLK>,
				 <&gcc GCC_MSS_AXIS2_CLK>,
				 <&gcc GCC_MSS_MFAB_AXIS_CLK>,
				 <&gcc GCC_PRNG_AHB_CLK>,
				 <&xo_board>;

			clock-names = "iface", "bus", "mem", "gpll0_mss",
				      "snoc_axi", "axis2", "mnoc_axi",
				      "prng", "xo";

			qcom,smem-states = <&modem_smp2p_out 0>;
			qcom,smem-state-names = "stop";

			resets = <&aoss_reset AOSS_CC_MSS_RESTART>;
			reset-names = "mss_restart";

			qcom,halt-regs = <&tcsr_mutex_regs
						0x23000 0x25000 0x24000>;

			power-domains = <&rpmhpd SDM845_CX>, <&rpmhpd SDM845_MX>, <&rpmhpd SDM845_MSS>;
			power-domain-names = "cx", "mx", "mss";

			mba {
				memory-region = <&mba_mem>;
			};

			mpss {
				memory-region = <&mpss_mem>;
			};

			glink-edge {
				interrupts = <0 449 IRQ_TYPE_EDGE_RISING>;
				label = "modem";
				qcom,remote-pid = <1>;
				mboxes = <&apss_shared 12>;
				mbox-names = "mpss_smem";
			};
		};

		gpu@5000000 {
			compatible = "qcom,adreno-630.2", "qcom,adreno";
			#stream-id-cells = <16>;

			reg = <0x5000000 0x40000>;
			reg-names = "kgsl_3d0_reg_memory";

			/*
			 * Look ma, no clocks! The GPU clocks and power are
			 * controlled entirely by the GMU
			 */

			interrupts = <0 300 IRQ_TYPE_LEVEL_HIGH>;
			interrupt-names = "kgsl_3d0_irq";

			iommus = <&kgsl_smmu 0>;

			operating-points-v2 = <&gpu_opp_table>;

			gmu = <&gmu>;
		};

		kgsl_smmu: arm,smmu-kgsl@5040000 {
			compatible = "qcom,sdm845-smmu-v2", "qcom,smmu-v2";
			reg = <0x5040000 0x10000>;
			#iommu-cells = <1>;
			#global-interrupts = <2>;
			interrupts = <GIC_SPI 229 IRQ_TYPE_LEVEL_HIGH>,
					<GIC_SPI 231 IRQ_TYPE_LEVEL_HIGH>,
					<GIC_SPI 364 IRQ_TYPE_EDGE_RISING>,
					<GIC_SPI 365 IRQ_TYPE_EDGE_RISING>,
					<GIC_SPI 366 IRQ_TYPE_EDGE_RISING>,
					<GIC_SPI 367 IRQ_TYPE_EDGE_RISING>,
					<GIC_SPI 368 IRQ_TYPE_EDGE_RISING>,
					<GIC_SPI 369 IRQ_TYPE_EDGE_RISING>,
					<GIC_SPI 370 IRQ_TYPE_EDGE_RISING>,
					<GIC_SPI 371 IRQ_TYPE_EDGE_RISING>;
			clocks = <&gcc GCC_GPU_MEMNOC_GFX_CLK>,
				<&gcc GCC_GPU_CFG_AHB_CLK>;
			clock-names = "bus", "iface";

			power-domains = <&gpucc GPU_CX_GDSC>;
		};

		gmu: gmu@506a000 {
			compatible="qcom,adreno-gmu";

			reg = <0x506a000 0x30000>, <0xb200000 0x300000>;
			reg-names = "gmu", "gmu_pdc";

			interrupts = <GIC_SPI 304 IRQ_TYPE_LEVEL_HIGH>,
				     <GIC_SPI 305 IRQ_TYPE_LEVEL_HIGH>;
			interrupt-names = "hfi", "gmu";

			clocks = <&gpucc GPU_CC_CX_GMU_CLK>,
				<&gpucc GPU_CC_CXO_CLK>,
				<&gcc GCC_DDRSS_GPU_AXI_CLK>,
				<&gcc GCC_GPU_MEMNOC_GFX_CLK>;
			clock-names = "gmu", "cxo", "axi", "memnoc";

			power-domains = <&gpucc GPU_CX_GDSC>;
			iommus = <&kgsl_smmu 5>;

			operating-points-v2 = <&gmu_opp_table>;
		};

		gpucc: clock-controller@5090000 {
			compatible = "qcom,sdm845-gpucc";
			reg = <0x5090000 0x9000>;
			#clock-cells = <1>;
			#reset-cells = <1>;
			#power-domain-cells = <1>;
		};

		sdhc_2: sdhci@8804000 {
			compatible = "qcom,sdhci-msm-v5";
			reg = <0x8804000 0x1000>;
			reg-names = "hc_mem";

			interrupts = <0 204 IRQ_TYPE_LEVEL_HIGH>, <0 222 IRQ_TYPE_LEVEL_HIGH>;
			interrupt-names = "hc_irq", "pwr_irq";

			qcom,bus-width = <4>;
			qcom,large-address-bus;

			qcom,clk-rates = <400000 20000000 25000000
					  50000000 100000000 201500000>;
			qcom,bus-speed-mode = "SDR12", "SDR25", "SDR50",
					      "DDR50", "SDR104";

			clocks = <&gcc GCC_SDCC2_AHB_CLK>,
				 <&gcc GCC_SDCC2_APPS_CLK>;
			clock-names = "iface", "core";

			status = "disabled";
		};

		qspi: qspi@88df000 {
			compatible = "qcom,qspi-v1";
			reg = <0x88df000 0x600>;
			#address-cells = <1>;
			#size-cells = <0>;
			interrupts = <GIC_SPI 82 IRQ_TYPE_LEVEL_HIGH>;
			clocks = <&gcc GCC_QSPI_CNOC_PERIPH_AHB_CLK>,
				 <&gcc GCC_QSPI_CORE_CLK>;
			clock-names = "iface", "core";
			status = "disabled";
		};

		usb_1_hsphy: phy@88e2000 {
			compatible = "qcom,sdm845-qusb2-phy";
			reg = <0x88e2000 0x400>;
			status = "disabled";
			#phy-cells = <0>;

			clocks = <&gcc GCC_USB_PHY_CFG_AHB2PHY_CLK>,
				 <&rpmhcc RPMH_CXO_CLK>;
			clock-names = "cfg_ahb", "ref";

			resets = <&gcc GCC_QUSB2PHY_PRIM_BCR>;

			nvmem-cells = <&qusb2p_hstx_trim>;
		};

		usb_2_hsphy: phy@88e3000 {
			compatible = "qcom,sdm845-qusb2-phy";
			reg = <0x88e3000 0x400>;
			status = "disabled";
			#phy-cells = <0>;

			clocks = <&gcc GCC_USB_PHY_CFG_AHB2PHY_CLK>,
				 <&rpmhcc RPMH_CXO_CLK>;
			clock-names = "cfg_ahb", "ref";

			resets = <&gcc GCC_QUSB2PHY_SEC_BCR>;

			nvmem-cells = <&qusb2s_hstx_trim>;
		};

		usb_1_qmpphy: phy@88e9000 {
			compatible = "qcom,sdm845-qmp-usb3-phy";
			reg = <0x88e9000 0x18c>,
			      <0x88e8000 0x10>;
			reg-names = "reg-base", "dp_com";
			status = "disabled";
			#clock-cells = <1>;
			#address-cells = <1>;
			#size-cells = <1>;
			ranges;

			clocks = <&gcc GCC_USB3_PRIM_PHY_AUX_CLK>,
				 <&gcc GCC_USB_PHY_CFG_AHB2PHY_CLK>,
				 <&gcc GCC_USB3_PRIM_CLKREF_CLK>,
				 <&gcc GCC_USB3_PRIM_PHY_COM_AUX_CLK>;
			clock-names = "aux", "cfg_ahb", "ref", "com_aux";

			resets = <&gcc GCC_USB3_DP_PHY_PRIM_BCR>,
				 <&gcc GCC_USB3_PHY_PRIM_BCR>;
			reset-names = "phy", "common";

			usb_1_ssphy: lane@88e9200 {
				reg = <0x88e9200 0x128>,
				      <0x88e9400 0x200>,
				      <0x88e9c00 0x218>,
				      <0x88e9a00 0x100>;
				#phy-cells = <0>;
				clocks = <&gcc GCC_USB3_PRIM_PHY_PIPE_CLK>;
				clock-names = "pipe0";
				clock-output-names = "usb3_phy_pipe_clk_src";
			};
		};

		usb_2_qmpphy: phy@88eb000 {
			compatible = "qcom,sdm845-qmp-usb3-uni-phy";
			reg = <0x88eb000 0x18c>;
			status = "disabled";
			#clock-cells = <1>;
			#address-cells = <1>;
			#size-cells = <1>;
			ranges;

			clocks = <&gcc GCC_USB3_SEC_PHY_AUX_CLK>,
				 <&gcc GCC_USB_PHY_CFG_AHB2PHY_CLK>,
				 <&gcc GCC_USB3_SEC_CLKREF_CLK>,
				 <&gcc GCC_USB3_SEC_PHY_COM_AUX_CLK>;
			clock-names = "aux", "cfg_ahb", "ref", "com_aux";

			resets = <&gcc GCC_USB3PHY_PHY_SEC_BCR>,
				 <&gcc GCC_USB3_PHY_SEC_BCR>;
			reset-names = "phy", "common";

			usb_2_ssphy: lane@88eb200 {
				reg = <0x88eb200 0x128>,
				      <0x88eb400 0x1fc>,
				      <0x88eb800 0x218>,
				      <0x88e9600 0x70>;
				#phy-cells = <0>;
				clocks = <&gcc GCC_USB3_SEC_PHY_PIPE_CLK>;
				clock-names = "pipe0";
				clock-output-names = "usb3_uni_phy_pipe_clk_src";
			};
		};

		usb_1: usb@a6f8800 {
			compatible = "qcom,sdm845-dwc3", "qcom,dwc3";
			reg = <0xa6f8800 0x400>;
			status = "disabled";
			#address-cells = <1>;
			#size-cells = <1>;
			ranges;

			clocks = <&gcc GCC_CFG_NOC_USB3_PRIM_AXI_CLK>,
				 <&gcc GCC_USB30_PRIM_MASTER_CLK>,
				 <&gcc GCC_AGGRE_USB3_PRIM_AXI_CLK>,
				 <&gcc GCC_USB30_PRIM_MOCK_UTMI_CLK>,
				 <&gcc GCC_USB30_PRIM_SLEEP_CLK>;
			clock-names = "cfg_noc", "core", "iface", "mock_utmi",
				      "sleep";

			assigned-clocks = <&gcc GCC_USB30_PRIM_MOCK_UTMI_CLK>,
					  <&gcc GCC_USB30_PRIM_MASTER_CLK>;
			assigned-clock-rates = <19200000>, <150000000>;

			interrupts = <GIC_SPI 131 IRQ_TYPE_LEVEL_HIGH>,
				     <GIC_SPI 486 IRQ_TYPE_LEVEL_HIGH>,
				     <GIC_SPI 488 IRQ_TYPE_LEVEL_HIGH>,
				     <GIC_SPI 489 IRQ_TYPE_LEVEL_HIGH>;
			interrupt-names = "hs_phy_irq", "ss_phy_irq",
					  "dm_hs_phy_irq", "dp_hs_phy_irq";

			power-domains = <&gcc USB30_PRIM_GDSC>;

			resets = <&gcc GCC_USB30_PRIM_BCR>;

			usb_1_dwc3: dwc3@a600000 {
				compatible = "snps,dwc3";
				reg = <0xa600000 0xcd00>;
				interrupts = <GIC_SPI 133 IRQ_TYPE_LEVEL_HIGH>;
				snps,dis_u2_susphy_quirk;
				snps,dis_enblslpm_quirk;
				phys = <&usb_1_hsphy>, <&usb_1_ssphy>;
				phy-names = "usb2-phy", "usb3-phy";
			};
		};

		usb_2: usb@a8f8800 {
			compatible = "qcom,sdm845-dwc3", "qcom,dwc3";
			reg = <0xa8f8800 0x400>;
			status = "disabled";
			#address-cells = <1>;
			#size-cells = <1>;
			ranges;

			clocks = <&gcc GCC_CFG_NOC_USB3_SEC_AXI_CLK>,
				 <&gcc GCC_USB30_SEC_MASTER_CLK>,
				 <&gcc GCC_AGGRE_USB3_SEC_AXI_CLK>,
				 <&gcc GCC_USB30_SEC_MOCK_UTMI_CLK>,
				 <&gcc GCC_USB30_SEC_SLEEP_CLK>;
			clock-names = "cfg_noc", "core", "iface", "mock_utmi",
				      "sleep";

			assigned-clocks = <&gcc GCC_USB30_SEC_MOCK_UTMI_CLK>,
					  <&gcc GCC_USB30_SEC_MASTER_CLK>;
			assigned-clock-rates = <19200000>, <150000000>;

			interrupts = <GIC_SPI 136 IRQ_TYPE_LEVEL_HIGH>,
				     <GIC_SPI 487 IRQ_TYPE_LEVEL_HIGH>,
				     <GIC_SPI 490 IRQ_TYPE_LEVEL_HIGH>,
				     <GIC_SPI 491 IRQ_TYPE_LEVEL_HIGH>;
			interrupt-names = "hs_phy_irq", "ss_phy_irq",
					  "dm_hs_phy_irq", "dp_hs_phy_irq";

			power-domains = <&gcc USB30_SEC_GDSC>;

			resets = <&gcc GCC_USB30_SEC_BCR>;

			usb_2_dwc3: dwc3@a800000 {
				compatible = "snps,dwc3";
				reg = <0xa800000 0xcd00>;
				interrupts = <GIC_SPI 138 IRQ_TYPE_LEVEL_HIGH>;
				snps,dis_u2_susphy_quirk;
				snps,dis_enblslpm_quirk;
				phys = <&usb_2_hsphy>, <&usb_2_ssphy>;
				phy-names = "usb2-phy", "usb3-phy";
			};
		};

		video-codec@aa00000 {
			compatible = "qcom,sdm845-venus";
			reg = <0x0aa00000 0xff000>;
			interrupts = <GIC_SPI 174 IRQ_TYPE_LEVEL_HIGH>;
			power-domains = <&videocc VENUS_GDSC>;
			clocks = <&videocc VIDEO_CC_VENUS_CTL_CORE_CLK>,
				<&videocc VIDEO_CC_VENUS_AHB_CLK>,
				<&videocc VIDEO_CC_VENUS_CTL_AXI_CLK>;
			clock-names = "core", "iface", "bus";
			iommus = <&apps_smmu 0x10a0 0x8>,
				<&apps_smmu 0x10b0 0x0>;
			memory-region = <&venus_region>;

			video-core0 {
				compatible = "venus-decoder";
				clocks = <&videocc VIDEO_CC_VCODEC0_CORE_CLK>,
					<&videocc VIDEO_CC_VCODEC0_AXI_CLK>;
				clock-names = "core", "bus";
				power-domains = <&videocc VCODEC0_GDSC>;
			};

			video-core1 {
				compatible = "venus-encoder";
				clocks = <&videocc VIDEO_CC_VCODEC1_CORE_CLK>,
					<&videocc VIDEO_CC_VCODEC1_AXI_CLK>;
				clock-names = "core", "bus";
				power-domains = <&videocc VCODEC1_GDSC>;
			};

			firmware {
				compatible = "qcom,venus-firmware";
				iommus = <&apps_smmu 0x10b2 0x0>;
			};
		};

		videocc: clock-controller@ab00000 {
			compatible = "qcom,sdm845-videocc";
			reg = <0xab00000 0x10000>;
			#clock-cells = <1>;
			#reset-cells = <1>;
			#power-domain-cells = <1>;
		};

		mdss: mdss@ae00000 {
			compatible = "qcom,sdm845-mdss";
			reg = <0xae00000 0x1000>;
			reg-names = "mdss";

			power-domains = <&dispcc 0>;

			clocks = <&gcc GCC_DISP_AHB_CLK>,
				 <&gcc GCC_DISP_AXI_CLK>,
				 <&dispcc DISP_CC_MDSS_MDP_CLK>;
			clock-names = "gcc_iface", "gcc_bus", "core";

			assigned-clocks = <&dispcc DISP_CC_MDSS_MDP_CLK>;
			assigned-clock-rates = <300000000>;

			interrupts = <GIC_SPI 83 IRQ_TYPE_LEVEL_HIGH>;
			interrupt-controller;
			#interrupt-cells = <1>;

			iommus = <&apps_smmu 0x880 0x8>,
				 <&apps_smmu 0xc80 0x8>;

			#address-cells = <2>;
			#size-cells = <1>;
			ranges = <0 0 0xae00000 0xb2008>;

			mdss_mdp: mdp@ae01000 {
				compatible = "qcom,sdm845-dpu";
				reg = <0 0x1000 0x8f000>, <0 0xb0000 0x2008>;
				reg-names = "mdp", "vbif";

				clocks = <&dispcc DISP_CC_MDSS_AHB_CLK>,
					 <&dispcc DISP_CC_MDSS_AXI_CLK>,
					 <&dispcc DISP_CC_MDSS_MDP_CLK>,
					 <&dispcc DISP_CC_MDSS_VSYNC_CLK>;
				clock-names = "iface", "bus", "core", "vsync";

				assigned-clocks =
					<&dispcc DISP_CC_MDSS_MDP_CLK>,
					<&dispcc DISP_CC_MDSS_VSYNC_CLK>;
				assigned-clock-rates = <300000000 19200000>;

				interrupts = <0 IRQ_TYPE_LEVEL_HIGH>;

				interconnects = <&qnoc 38 &qnoc 512>,
						<&qnoc 39 &qnoc 512>;
				interconnect-names = "port0", "port1";

				ports {
					#address-cells = <1>;
					#size-cells = <0>;

					port@0 {
						reg = <0>;
						dpu_intf1_out: endpoint {
							remote-endpoint = <&dsi0_in>;
						};
					};

					port@1 {
						reg = <1>;
						dpu_intf2_out: endpoint {
							remote-endpoint = <&dsi1_in>;
						};
					};
				};

			};

			dsi0: dsi@ae94000 {
				compatible = "qcom,mdss-dsi-ctrl";
				reg = <0 0x94000 0x400>;
				reg-names = "dsi_ctrl";

				interrupt-parent = <&mdss>;
				interrupts = <4 0>;

				clocks = <&dispcc DISP_CC_MDSS_BYTE0_CLK>,
					 <&dispcc DISP_CC_MDSS_BYTE0_INTF_CLK>,
					 <&dispcc DISP_CC_MDSS_PCLK0_CLK>,
					 <&dispcc DISP_CC_MDSS_ESC0_CLK>,
					 <&dispcc DISP_CC_MDSS_AHB_CLK>,
					 <&dispcc DISP_CC_MDSS_AXI_CLK>;
				clock-names = "byte",
					      "byte_intf",
					      "pixel",
					      "core",
					      "iface",
					      "bus";

				phys = <&dsi0_phy>;
				phy-names = "dsi-phy";

				#address-cells = <1>;
				#size-cells = <0>;

				ports {
					#address-cells = <1>;
					#size-cells = <0>;

					port@0 {
						reg = <0>;
						dsi0_in: endpoint {
							remote-endpoint = <&dpu_intf1_out>;
						};
					};

					port@1 {
						reg = <1>;
						dsi0_out: endpoint {
						};
					};
				};
			};

			dsi0_phy: dsi-phy@ae94400 {
				compatible = "qcom,dsi-phy-10nm";
				reg = <0 0x94400 0x200>,
				      <0 0x94a00 0x1e0>,
				      <0 0x94600 0x280>;
				reg-names = "dsi_phy",
					    "dsi_pll",
						"dsi_phy_lane";
				#phy-cells = <0>;
				#clock-cells = <1>;

				clocks = <&dispcc DISP_CC_MDSS_AHB_CLK>;
				clock-names = "iface";
			};

			dsi1: dsi@ae96000 {
				compatible = "qcom,mdss-dsi-ctrl";
				reg = <0 0x96000 0x400>;
				reg-names = "dsi_ctrl";

				interrupt-parent = <&mdss>;
				interrupts = <5 0>;

				clocks = <&dispcc DISP_CC_MDSS_BYTE1_CLK>,
					 <&dispcc DISP_CC_MDSS_BYTE1_INTF_CLK>,
					 <&dispcc DISP_CC_MDSS_PCLK1_CLK>,
					 <&dispcc DISP_CC_MDSS_ESC1_CLK>,
					 <&dispcc DISP_CC_MDSS_AHB_CLK>,
					 <&dispcc DISP_CC_MDSS_AXI_CLK>;
				clock-names = "byte",
					      "byte_intf",
					      "pixel",
					      "core",
					      "iface",
					      "bus";

				phys = <&dsi1_phy>;
				phy-names = "dsi-phy";

				#address-cells = <1>;
				#size-cells = <0>;

				ports {
					#address-cells = <1>;
					#size-cells = <0>;

					port@0 {
						reg = <0>;
						dsi1_in: endpoint {
							remote-endpoint = <&dpu_intf2_out>;
						};
					};

					port@1 {
						reg = <1>;
						dsi1_out: endpoint {
						};
					};
				};
			};

			dsi1_phy: dsi-phy@ae96400 {
				compatible = "qcom,dsi-phy-10nm";
				reg = <0 0x96400 0x200>,
				      <0 0x96a00 0x10e>,
					<0 0x96600 0x280>;
				reg-names = "dsi_phy",
					    "dsi_pll",
						"dsi_phy_lane";

				#phy-cells = <0>;
				#clock-cells = <1>;

				clocks = <&dispcc DISP_CC_MDSS_AHB_CLK>;
				clock-names = "iface";
			};
		};

		dispcc: clock-controller@af00000 {
			compatible = "qcom,sdm845-dispcc";
			reg = <0xaf00000 0x10000>;
			#clock-cells = <1>;
			#reset-cells = <1>;
			#power-domain-cells = <1>;
		};

		aoss_reset: qcom,reset-controller@b2e0100 {
			compatible = "qcom,sdm845-aoss-reset";
			reg = <0xc2b0000 0x20004>;
			#reset-cells = <1>;
		};

		tsens0: thermal-sensor@c263000 {
			compatible = "qcom,sdm845-tsens", "qcom,tsens-v2";
			reg = <0xc263000 0x1ff>, /* TM */
			      <0xc222000 0x1ff>; /* SROT */
			#qcom,sensors = <13>;
			#thermal-sensor-cells = <1>;
		};

		tsens1: thermal-sensor@c265000 {
			compatible = "qcom,sdm845-tsens", "qcom,tsens-v2";
			reg = <0xc265000 0x1ff>, /* TM */
			      <0xc223000 0x1ff>; /* SROT */
			#qcom,sensors = <8>;
			#thermal-sensor-cells = <1>;
		};

		spmi_bus: spmi@c440000 {
			compatible = "qcom,spmi-pmic-arb";
			reg = <0xc440000 0x1100>,
			      <0xc600000 0x2000000>,
			      <0xe600000 0x100000>,
			      <0xe700000 0xa0000>,
			      <0xc40a000 0x26000>;
			reg-names = "core", "chnls", "obsrvr", "intr", "cnfg";
			interrupt-names = "periph_irq";
			interrupts = <GIC_SPI 481 IRQ_TYPE_LEVEL_HIGH>;
			qcom,ee = <0>;
			qcom,channel = <0>;
			#address-cells = <2>;
			#size-cells = <0>;
			interrupt-controller;
			#interrupt-cells = <4>;
			cell-index = <0>;
		};

		apps_smmu: iommu@15000000 {
			compatible = "qcom,sdm845-smmu-500", "arm,mmu-500";
			reg = <0x15000000 0x80000>;
			#iommu-cells = <2>;
			#global-interrupts = <1>;
			interrupts = <GIC_SPI 65 IRQ_TYPE_LEVEL_HIGH>,
				     <GIC_SPI 96 IRQ_TYPE_LEVEL_HIGH>,
				     <GIC_SPI 97 IRQ_TYPE_LEVEL_HIGH>,
				     <GIC_SPI 98 IRQ_TYPE_LEVEL_HIGH>,
				     <GIC_SPI 99 IRQ_TYPE_LEVEL_HIGH>,
				     <GIC_SPI 100 IRQ_TYPE_LEVEL_HIGH>,
				     <GIC_SPI 101 IRQ_TYPE_LEVEL_HIGH>,
				     <GIC_SPI 102 IRQ_TYPE_LEVEL_HIGH>,
				     <GIC_SPI 103 IRQ_TYPE_LEVEL_HIGH>,
				     <GIC_SPI 104 IRQ_TYPE_LEVEL_HIGH>,
				     <GIC_SPI 105 IRQ_TYPE_LEVEL_HIGH>,
				     <GIC_SPI 106 IRQ_TYPE_LEVEL_HIGH>,
				     <GIC_SPI 107 IRQ_TYPE_LEVEL_HIGH>,
				     <GIC_SPI 108 IRQ_TYPE_LEVEL_HIGH>,
				     <GIC_SPI 109 IRQ_TYPE_LEVEL_HIGH>,
				     <GIC_SPI 110 IRQ_TYPE_LEVEL_HIGH>,
				     <GIC_SPI 111 IRQ_TYPE_LEVEL_HIGH>,
				     <GIC_SPI 112 IRQ_TYPE_LEVEL_HIGH>,
				     <GIC_SPI 113 IRQ_TYPE_LEVEL_HIGH>,
				     <GIC_SPI 114 IRQ_TYPE_LEVEL_HIGH>,
				     <GIC_SPI 115 IRQ_TYPE_LEVEL_HIGH>,
				     <GIC_SPI 116 IRQ_TYPE_LEVEL_HIGH>,
				     <GIC_SPI 117 IRQ_TYPE_LEVEL_HIGH>,
				     <GIC_SPI 118 IRQ_TYPE_LEVEL_HIGH>,
				     <GIC_SPI 181 IRQ_TYPE_LEVEL_HIGH>,
				     <GIC_SPI 182 IRQ_TYPE_LEVEL_HIGH>,
				     <GIC_SPI 183 IRQ_TYPE_LEVEL_HIGH>,
				     <GIC_SPI 184 IRQ_TYPE_LEVEL_HIGH>,
				     <GIC_SPI 185 IRQ_TYPE_LEVEL_HIGH>,
				     <GIC_SPI 186 IRQ_TYPE_LEVEL_HIGH>,
				     <GIC_SPI 187 IRQ_TYPE_LEVEL_HIGH>,
				     <GIC_SPI 188 IRQ_TYPE_LEVEL_HIGH>,
				     <GIC_SPI 189 IRQ_TYPE_LEVEL_HIGH>,
				     <GIC_SPI 190 IRQ_TYPE_LEVEL_HIGH>,
				     <GIC_SPI 191 IRQ_TYPE_LEVEL_HIGH>,
				     <GIC_SPI 192 IRQ_TYPE_LEVEL_HIGH>,
				     <GIC_SPI 315 IRQ_TYPE_LEVEL_HIGH>,
				     <GIC_SPI 316 IRQ_TYPE_LEVEL_HIGH>,
				     <GIC_SPI 317 IRQ_TYPE_LEVEL_HIGH>,
				     <GIC_SPI 318 IRQ_TYPE_LEVEL_HIGH>,
				     <GIC_SPI 319 IRQ_TYPE_LEVEL_HIGH>,
				     <GIC_SPI 320 IRQ_TYPE_LEVEL_HIGH>,
				     <GIC_SPI 321 IRQ_TYPE_LEVEL_HIGH>,
				     <GIC_SPI 322 IRQ_TYPE_LEVEL_HIGH>,
				     <GIC_SPI 323 IRQ_TYPE_LEVEL_HIGH>,
				     <GIC_SPI 324 IRQ_TYPE_LEVEL_HIGH>,
				     <GIC_SPI 325 IRQ_TYPE_LEVEL_HIGH>,
				     <GIC_SPI 326 IRQ_TYPE_LEVEL_HIGH>,
				     <GIC_SPI 327 IRQ_TYPE_LEVEL_HIGH>,
				     <GIC_SPI 328 IRQ_TYPE_LEVEL_HIGH>,
				     <GIC_SPI 329 IRQ_TYPE_LEVEL_HIGH>,
				     <GIC_SPI 330 IRQ_TYPE_LEVEL_HIGH>,
				     <GIC_SPI 331 IRQ_TYPE_LEVEL_HIGH>,
				     <GIC_SPI 332 IRQ_TYPE_LEVEL_HIGH>,
				     <GIC_SPI 333 IRQ_TYPE_LEVEL_HIGH>,
				     <GIC_SPI 334 IRQ_TYPE_LEVEL_HIGH>,
				     <GIC_SPI 335 IRQ_TYPE_LEVEL_HIGH>,
				     <GIC_SPI 336 IRQ_TYPE_LEVEL_HIGH>,
				     <GIC_SPI 337 IRQ_TYPE_LEVEL_HIGH>,
				     <GIC_SPI 338 IRQ_TYPE_LEVEL_HIGH>,
				     <GIC_SPI 339 IRQ_TYPE_LEVEL_HIGH>,
				     <GIC_SPI 340 IRQ_TYPE_LEVEL_HIGH>,
				     <GIC_SPI 341 IRQ_TYPE_LEVEL_HIGH>,
				     <GIC_SPI 342 IRQ_TYPE_LEVEL_HIGH>,
				     <GIC_SPI 343 IRQ_TYPE_LEVEL_HIGH>;
		};

		apss_shared: mailbox@17990000 {
			compatible = "qcom,sdm845-apss-shared";
			reg = <0x17990000 0x1000>;
			#mbox-cells = <1>;
		};

		/* TODO: conflicts w/ above? */
		apcs: syscon@1799000c {
			compatible = "syscon";
			reg = <0x1799000c 0x4>;
		};

		apps_rsc: rsc@179c0000 {
			label = "apps_rsc";
			compatible = "qcom,rpmh-rsc";
			reg = <0x179c0000 0x10000>,
			      <0x179d0000 0x10000>,
			      <0x179e0000 0x10000>;
			reg-names = "drv-0", "drv-1", "drv-2";
			interrupts = <GIC_SPI 3 IRQ_TYPE_LEVEL_HIGH>,
				     <GIC_SPI 4 IRQ_TYPE_LEVEL_HIGH>,
				     <GIC_SPI 5 IRQ_TYPE_LEVEL_HIGH>;
			qcom,tcs-offset = <0xd00>;
			qcom,drv-id = <2>;
			qcom,tcs-config = <ACTIVE_TCS  2>,
					  <SLEEP_TCS   3>,
					  <WAKE_TCS    3>,
					  <CONTROL_TCS 1>;

			rpmhcc: clock-controller {
				compatible = "qcom,sdm845-rpmh-clk";
				#clock-cells = <1>;
			};

			rpmhpd_opp_table: opp-table {
				compatible = "operating-points-v2-qcom-level";

				rpmhpd_opp_ret: opp1 {
					qcom,level = <RPMH_REGULATOR_LEVEL_RETENTION>;
				};

				rpmhpd_opp_min_svs: opp2 {
					qcom,level = <RPMH_REGULATOR_LEVEL_MIN_SVS>;
				};

				rpmhpd_opp_low_svs: opp3 {
					qcom,level = <RPMH_REGULATOR_LEVEL_LOW_SVS>;
				};

				rpmhpd_opp_svs: opp4 {
					qcom,level = <RPMH_REGULATOR_LEVEL_SVS>;
				};

				rpmhpd_opp_svs_l1: opp5 {
					qcom,level = <RPMH_REGULATOR_LEVEL_SVS_L1>;
				};

				rpmhpd_opp_nom: opp6 {
					qcom,level = <RPMH_REGULATOR_LEVEL_NOM>;
				};

				rpmhpd_opp_nom_l1: opp7 {
					qcom,level = <RPMH_REGULATOR_LEVEL_NOM_L1>;
				};

				rpmhpd_opp_nom_l2: opp8 {
					qcom,level = <RPMH_REGULATOR_LEVEL_NOM_L2>;
				};

				rpmhpd_opp_turbo: opp9 {
					qcom,level = <RPMH_REGULATOR_LEVEL_TURBO>;
				};

				rpmhpd_opp_turbo_l1: opp10 {
					qcom,level = <RPMH_REGULATOR_LEVEL_TURBO_L1>;
				};
			};

			rpmhpd: power-controller {
				compatible = "qcom,sdm845-rpmhpd";
				#power-domain-cells = <1>;
				operating-points-v2 = <&rpmhpd_opp_table>;
			};

			qnoc: qnoc{
				compatible = "qcom,sdm845-rsc-hlos";
				#interconnect-cells = <1>;
			};
		};

		intc: interrupt-controller@17a00000 {
			compatible = "arm,gic-v3";
			#address-cells = <1>;
			#size-cells = <1>;
			ranges;
			#interrupt-cells = <3>;
			interrupt-controller;
			reg = <0x17a00000 0x10000>,     /* GICD */
			      <0x17a60000 0x100000>;    /* GICR * 8 */
			interrupts = <GIC_PPI 9 IRQ_TYPE_LEVEL_HIGH>;

			gic-its@17a40000 {
				compatible = "arm,gic-v3-its";
				msi-controller;
				#msi-cells = <1>;
				reg = <0x17a40000 0x20000>;
				status = "disabled";
			};
		};

		timer@17c90000 {
			#address-cells = <1>;
			#size-cells = <1>;
			ranges;
			compatible = "arm,armv7-timer-mem";
			reg = <0x17c90000 0x1000>;

			frame@17ca0000 {
				frame-number = <0>;
				interrupts = <GIC_SPI 7 IRQ_TYPE_LEVEL_HIGH>,
					     <GIC_SPI 6 IRQ_TYPE_LEVEL_HIGH>;
				reg = <0x17ca0000 0x1000>,
				      <0x17cb0000 0x1000>;
			};

			frame@17cc0000 {
				frame-number = <1>;
				interrupts = <GIC_SPI 8 IRQ_TYPE_LEVEL_HIGH>;
				reg = <0x17cc0000 0x1000>;
				status = "disabled";
			};

			frame@17cd0000 {
				frame-number = <2>;
				interrupts = <GIC_SPI 9 IRQ_TYPE_LEVEL_HIGH>;
				reg = <0x17cd0000 0x1000>;
				status = "disabled";
			};

			frame@17ce0000 {
				frame-number = <3>;
				interrupts = <GIC_SPI 10 IRQ_TYPE_LEVEL_HIGH>;
				reg = <0x17ce0000 0x1000>;
				status = "disabled";
			};

			frame@17cf0000 {
				frame-number = <4>;
				interrupts = <GIC_SPI 11 IRQ_TYPE_LEVEL_HIGH>;
				reg = <0x17cf0000 0x1000>;
				status = "disabled";
			};

			frame@17d00000 {
				frame-number = <5>;
				interrupts = <GIC_SPI 12 IRQ_TYPE_LEVEL_HIGH>;
				reg = <0x17d00000 0x1000>;
				status = "disabled";
			};

			frame@17d10000 {
				frame-number = <6>;
				interrupts = <GIC_SPI 13 IRQ_TYPE_LEVEL_HIGH>;
				reg = <0x17d10000 0x1000>;
				status = "disabled";
			};
		};

		adsp-smp2p {
			compatible = "qcom,smp2p";
			qcom,smem = <443>, <429>;
			interrupts = <GIC_SPI 158 IRQ_TYPE_EDGE_RISING>;
			qcom,ipc = <&apcs 0 10>;
			qcom,local-pid = <0>;
			qcom,remote-pid = <2>;

			adsp_smp2p_out: master-kernel {
				qcom,entry-name = "master-kernel";
				#qcom,smem-state-cells = <1>;
			};

			adsp_smp2p_in: slave-kernel {
				qcom,entry-name = "slave-kernel";
				interrupt-controller;
				#interrupt-cells = <2>;
			};
		};

		cdsp-smp2p {
			compatible = "qcom,smp2p";
			qcom,smem = <94>, <432>;
			interrupts = <GIC_SPI 576 IRQ_TYPE_EDGE_RISING>;
			qcom,ipc = <&apcs 0 6>;
			qcom,local-pid = <0>;
			qcom,remote-pid = <5>;

			cdsp_smp2p_out: master-kernel {
				qcom,entry-name = "master-kernel";
				#qcom,smem-state-cells = <1>;
			};

			cdsp_smp2p_in: slave-kernel {
				qcom,entry-name = "slave-kernel";
				interrupt-controller;
				#interrupt-cells = <2>;
			};
		};

		dsps-smp2p {
			compatible = "qcom,smp2p";
			qcom,smem = <481>, <430>;
			interrupts = <GIC_SPI 172 IRQ_TYPE_EDGE_RISING>;
			qcom,ipc = <&apcs 0 26>;
			qcom,local-pid = <0>;
			qcom,remote-pid = <3>;

			dsps_smp2p_out: master-kernel {
				qcom,entry-name = "master-kernel";
				#qcom,smem-state-cells = <1>;
			};

			dsps_smp2p_in: slave-kernel {
				qcom,entry-name = "slave-kernel";
				interrupt-controller;
				#interrupt-cells = <2>;
			};
		};

		gpu_opp_table: adreno-opp-table {
			compatible = "operating-points-v2";

			opp-710000000 {
				opp-hz = /bits/ 64 <710000000>;
				qcom,level = <416>;
			};

			opp-675000000 {
				opp-hz = /bits/ 64 <675000000>;
				qcom,level = <384>;
			};

			opp-596000000 {
				opp-hz = /bits/ 64 <596000000>;
				qcom,level = <320>;
			};

			opp-520000000 {
				opp-hz = /bits/ 64 <520000000>;
				qcom,level = <256>;
			};

			opp-414000000 {
				opp-hz = /bits/ 64 <414000000>;
				qcom,level = <192>;
			};

			opp-342000000 {
				opp-hz = /bits/ 64 <342000000>;
				qcom,level = <128>;
			};

			opp-257000000 {
				opp-hz = /bits/ 64 <257000000>;
				qcom,level = <64>;
			};
		};

		gmu_opp_table: adreno-gmu-opp-table {
			compatible = "operating-points-v2";

			opp-400000000 {
				opp-hz = /bits/ 64 <400000000>;
				qcom,level = <128>;
			};

			opp-200000000 {
				opp-hz = /bits/ 64 <200000000>;
				qcom,level = <48>;
			};
		};

		modem-smp2p {
			compatible = "qcom,smp2p";
			qcom,smem = <435>, <428>;
			interrupts = <GIC_SPI 451 IRQ_TYPE_EDGE_RISING>;
			qcom,ipc = <&apcs 0 14>;
			qcom,local-pid = <0>;
			qcom,remote-pid = <1>;

			modem_smp2p_out: master-kernel {
				qcom,entry-name = "master-kernel";
				#qcom,smem-state-cells = <1>;
			};

			modem_smp2p_in: slave-kernel {
				qcom,entry-name = "slave-kernel";
				interrupt-controller;
				#interrupt-cells = <2>;
			};

			ipa_smp2p_out: ipa-ap-to-modem {
				qcom,entry-name = "ipa";
				#qcom,smem-state-cells = <1>;
			};

			ipa_smp2p_in: ipa-modem-to-ap {
				qcom,entry-name = "ipa";
				interrupt-controller;
				#interrupt-cells = <2>;
			};
		};
	};
};
